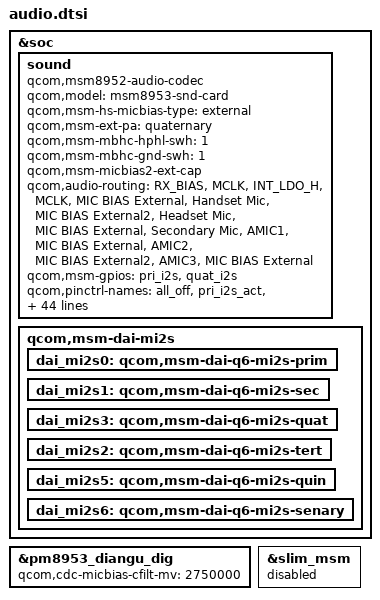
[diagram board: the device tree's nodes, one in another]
&soc {
	/delete-node/ hd3ss460;

	sound {
		status = "okay";
		compatible = "qcom,msm8952-audio-codec";
		qcom,model = "msm8953-snd-card";
		qcom,msm-hs-micbias-type = "external";
		qcom,msm-ext-pa = "quaternary";
		qcom,msm-mbhc-hphl-swh = <1>;
		qcom,msm-mbhc-gnd-swh = <1>;
		qcom,msm-micbias2-ext-cap;

		qcom,audio-routing =
			"RX_BIAS", "MCLK",
			"INT_LDO_H", "MCLK",
			"MIC BIAS External", "Handset Mic",
			"MIC BIAS External2", "Headset Mic",
			"MIC BIAS External", "Secondary Mic",
			"AMIC1", "MIC BIAS External",
			"AMIC2", "MIC BIAS External2",
			"AMIC3", "MIC BIAS External";

		/delete-property/ asoc-wsa-codec-names;
		/delete-property/ asoc-wsa-codec-prefixes;
		/delete-property/ msm-vdd-wsa-switch-supply;
		/delete-property/ qcom,msm-vdd-wsa-switch-voltage;
		/delete-property/ qcom,msm-vdd-wsa-switch-current;
		/delete-property/ qcom,hdmi-dba-codec-rx;
		/delete-property/ qcom,cdc-us-euro-gpios;
		/delete-property/ pinctrl-4;
		/delete-property/ pinctrl-5;
		/delete-property/ pinctrl-6;
		/delete-property/ pinctrl-7;
		/delete-property/ pinctrl-8;
		/delete-property/ pinctrl-9;
		/delete-property/ pinctrl-10;
		/delete-property/ pinctrl-11;
		/delete-property/ pinctrl-12;
		/delete-property/ pinctrl-13;
		/delete-property/ pinctrl-14;
		/delete-property/ pinctrl-15;

		qcom,msm-gpios =
			"pri_i2s",
			"quat_i2s";
		qcom,pinctrl-names =
			"all_off",
			"pri_i2s_act",
			"quat_i2s_act",
			"quat_pri_i2s_act";
		pinctrl-names =
			"all_off",
			"pri_i2s_act",
			"quat_i2s_act",
			"quat_pri_i2s_act";

		pinctrl-0 = <&cdc_pdm_lines_sus
				&cdc_pdm_lines_2_sus
				&sec_tlmm_lines_sus>;
		pinctrl-1 = <&cdc_pdm_lines_act
				&cdc_pdm_lines_2_act
				&sec_tlmm_lines_sus>;
		pinctrl-2 = <&cdc_pdm_lines_sus
				&cdc_pdm_lines_2_sus
				&sec_tlmm_lines_act>;
		pinctrl-3 = <&cdc_pdm_lines_act
				&cdc_pdm_lines_2_act
				&sec_tlmm_lines_act>;


		asoc-platform = <&pcm0>, <&pcm1>, <&pcm2>, <&voip>, <&voice>,
			<&loopback>, <&compress>, <&hostless>,
			<&afe>, <&lsm>, <&routing>, <&cpe>, <&lpa>;
		asoc-platform-names = "msm-pcm-dsp.0", "msm-pcm-dsp.1",
			"msm-pcm-dsp.2", "msm-voip-dsp",
			"msm-pcm-voice", "msm-pcm-loopback",
			"msm-compress-dsp", "msm-pcm-hostless",
			"msm-pcm-afe", "msm-lsm-client",
			"msm-pcm-routing", "msm-cpe-lsm",
			"msm-pcm-lpa";

		asoc-cpu = <&dai_pri_auxpcm>,
				<&dai_mi2s0>, <&dai_mi2s1>,
				<&dai_mi2s2>, <&dai_mi2s3>,
				<&dai_mi2s5>, <&dai_mi2s6>,
				<&sb_0_rx>, <&sb_0_tx>, <&sb_1_rx>, <&sb_1_tx>,
				<&sb_3_rx>, <&sb_3_tx>, <&sb_4_rx>, <&sb_4_tx>,
				<&bt_sco_rx>, <&bt_sco_tx>,
				<&int_fm_rx>, <&int_fm_tx>,
				<&afe_pcm_rx>, <&afe_pcm_tx>,
				<&afe_proxy_rx>, <&afe_proxy_tx>,
				<&incall_record_rx>, <&incall_record_tx>,
				<&incall_music_rx>, <&incall_music_2_rx>;
		asoc-cpu-names = "msm-dai-q6-auxpcm.1",
				"msm-dai-q6-mi2s.0", "msm-dai-q6-mi2s.1",
				"msm-dai-q6-mi2s.2", "msm-dai-q6-mi2s.3",
				"msm-dai-q6-mi2s.5", "msm-dai-q6-mi2s.6",
				"msm-dai-q6-dev.16384", "msm-dai-q6-dev.16385",
				"msm-dai-q6-dev.16386", "msm-dai-q6-dev.16387",
				"msm-dai-q6-dev.16390", "msm-dai-q6-dev.16391",
				"msm-dai-q6-dev.16392", "msm-dai-q6-dev.16393",
				"msm-dai-q6-dev.12288", "msm-dai-q6-dev.12289",
				"msm-dai-q6-dev.12292", "msm-dai-q6-dev.12293",
				"msm-dai-q6-dev.224", "msm-dai-q6-dev.225",
				"msm-dai-q6-dev.241", "msm-dai-q6-dev.240",
				"msm-dai-q6-dev.32771", "msm-dai-q6-dev.32772",
				"msm-dai-q6-dev.32773", "msm-dai-q6-dev.32770";
		asoc-codec = <&stub_codec>, <&pm8953_diangu_dig>;
		asoc-codec-names = "msm-stub-codec.1", "cajon_codec";
	};

	qcom,msm-dai-mi2s {
		status = "okay";
		dai_mi2s0: qcom,msm-dai-q6-mi2s-prim {
			status = "okay";
		};

		dai_mi2s1: qcom,msm-dai-q6-mi2s-sec {
			status = "okay";
		};

		dai_mi2s3: qcom,msm-dai-q6-mi2s-quat {
			status = "okay";
			/delete-property/ pinctrl-names;
			/delete-property/ pinctrl-0;
			/delete-property/ pinctrl-1;
		};

		dai_mi2s2: qcom,msm-dai-q6-mi2s-tert {
			status = "okay";
		};

		dai_mi2s5: qcom,msm-dai-q6-mi2s-quin {
			status = "okay";
			/delete-property/ pinctrl-names;
			/delete-property/ pinctrl-0;
			/delete-property/ pinctrl-1;
		};

		dai_mi2s6: qcom,msm-dai-q6-mi2s-senary {
			status = "okay";
		};
	};
};

&pm8953_diangu_dig{
	qcom,cdc-micbias-cfilt-mv = <2750000>;
};


&slim_msm {
	status = "disabled";
	/delete-node/ tasha_codec;
	/delete-node/ marley-codec;
};
